# MSP430FR5739 register map
File version: 1.1
CPU: msp430
Registers are 16-bit, access not given, reset 0x0 unless marked. A register's access mark holds for its fields unless they carry their own. Offsets are from the block's base; [hi:lo] are bit positions; {n}, {i} and the like mark numbered series.

## USCI_B0__I2C_Mode
Base 0x00000000
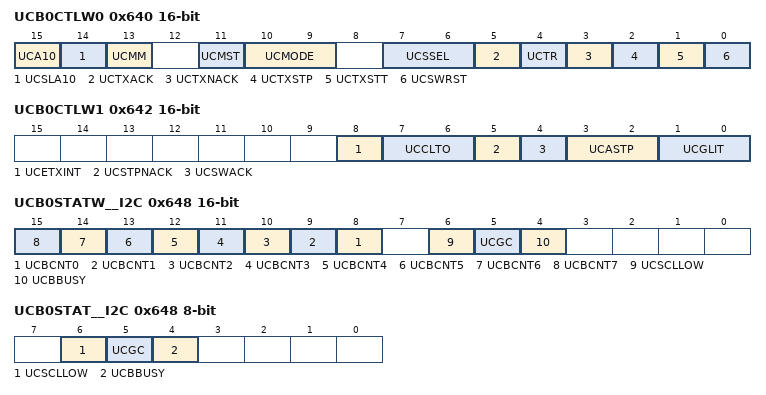
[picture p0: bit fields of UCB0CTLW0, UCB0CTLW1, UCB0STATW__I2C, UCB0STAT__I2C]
0x640 UCB0CTLW0 — USCI B0 Control Word Register 0
  [15] UCA10 — [15:15] 10-bit Address Mode
  [14] UCSLA10 — [14:14] 10-bit Slave Address Mode
  [13] UCMM — [13:13] Multi-Master Environment
  [11] UCMST — [11:11] Sync. Mode: Master Select
  [10:9] UCMODE — [10:9] Sync. Mode: USCI Mode 1
    {v}=Sync. Mode: USCI Mode: {v} (v=0..3)
  [7:6] UCSSEL — [7:6] USCI 1 Clock Source Select 1
    {v}=USCI 0 Clock Source: {v} (v=0..3)
  [5] UCTXACK — [5:5] Transmit ACK
  [4] UCTR — [4:4] Transmit/Receive Select/Flag
  [3] UCTXNACK — [3:3] Transmit NACK
  [2] UCTXSTP — [2:2] Transmit STOP
  [1] UCTXSTT — [1:1] Transmit START
  [0] UCSWRST — [0:0] USCI Software Reset
0x640 UCB0CTL1 8-bit — USCI B0 Control Register 1
0x641 UCB0CTL0 8-bit — USCI B0 Control Register 0
0x642 UCB0CTLW1 — USCI B0 Control Word Register 1
  [8] UCETXINT — [8:8] USCI Early UCTXIFG0
  [7:6] UCCLTO — [7:6] USCI Clock low timeout Bit: 1
    {v}=USCI Clock low timeout: {v} (v=0..3)
  [5] UCSTPNACK — [5:5] USCI Acknowledge Stop last byte
  [4] UCSWACK — [4:4] USCI Software controlled ACK
  [3:2] UCASTP — [3:2] USCI Automatic Stop condition generation Bit: 1
    {v}=USCI Automatic Stop condition generation: {v} (v=0..3)
  [1:0] UCGLIT — [1:0] USCI Deglitch time Bit: 1
    {v}=USCI Deglitch time: {v} (v=0..3)
0x646 UCB0BRW — USCI B0 Baud Word Rate 0
0x646 UCB0BR0 8-bit — USCI B0 Baud Rate 0
0x647 UCB0BR1 8-bit — USCI B0 Baud Rate 1
0x648 UCB0STATW — USCI B0 Status Word Register
0x648 UCB0STATW__I2C — USCI B0 Status Register
  [n+8] UCBCNT{n} (n=0..7) — [{n+8}:{n+8}] USCI Byte Counter Bit {n}
  [6] UCSCLLOW — [6:6] SCL low
  [5] UCGC — [5:5] General Call address received Flag
  [4] UCBBUSY — [4:4] Bus Busy Flag
0x648 UCB0STAT__I2C 8-bit — USCI B0 Status Register
  [6] UCSCLLOW — [6:6] SCL low
  [5] UCGC — [5:5] General Call address received Flag
  [4] UCBBUSY — [4:4] Bus Busy Flag
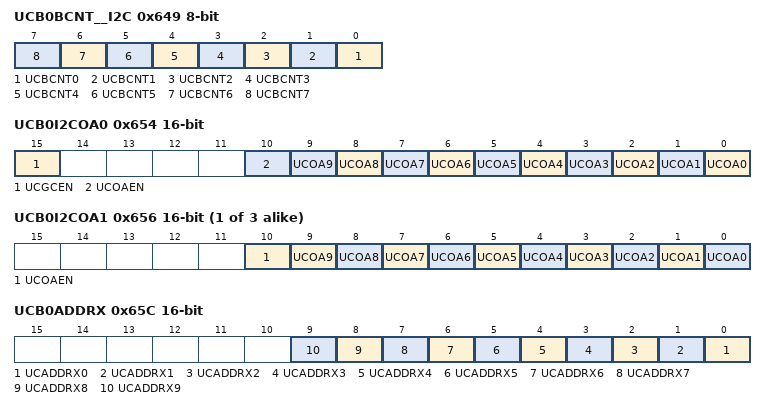
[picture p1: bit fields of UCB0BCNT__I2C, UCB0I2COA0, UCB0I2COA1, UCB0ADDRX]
0x649 UCB0BCNT__I2C 8-bit — USCI B0 Byte Counter Register
  [n] UCBCNT{n} (n=0..7) — [{n}:{n}] USCI Byte Counter Bit {n}
0x64A UCB0TBCNT — USCI B0 Byte Counter Threshold Register
0x64C UCB0RXBUF — USCI B0 Receive Buffer
0x64E UCB0TXBUF — USCI B0 Transmit Buffer
0x654 UCB0I2COA0 — USCI B0 I2C Own Address 0
  [15] UCGCEN — [15:15] I2C General Call enable
  [10] UCOAEN — [10:10] I2C Own Address enable
  [n] UCOA{n} (n=0..9) — [{n}:{n}] I2C Own Address Bit {n}
{0x654+2i} UCB0I2COA{i} (i=1..3) — USCI B0 I2C Own Address {i}
  [10] UCOAEN — [10:10] I2C Own Address enable
  [n] UCOA{n} (n=0..9) — [{n}:{n}] I2C Own Address Bit {n}
0x65C UCB0ADDRX — USCI B0 Received Address Register
  [n] UCADDRX{n} (n=0..9) — [{n}:{n}] I2C Receive Address Bit {n}
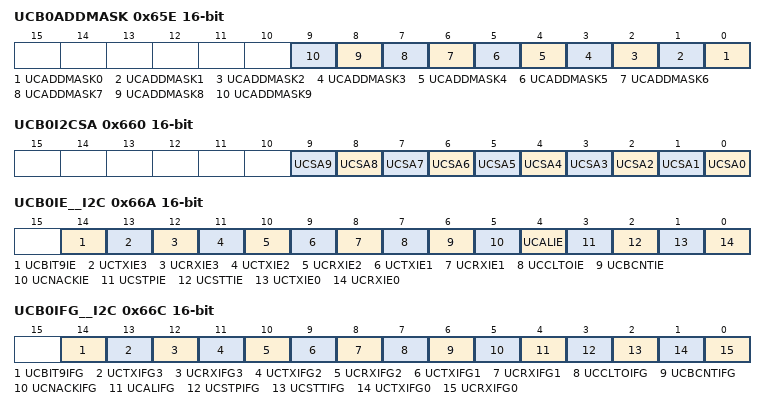
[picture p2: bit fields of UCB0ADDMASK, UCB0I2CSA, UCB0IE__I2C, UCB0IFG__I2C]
0x65E UCB0ADDMASK — USCI B0 Address Mask Register
  [n] UCADDMASK{n} (n=0..9) — [{n}:{n}] I2C Address Mask Bit {n}
0x660 UCB0I2CSA — USCI B0 I2C Slave Address
  [n] UCSA{n} (n=0..9) — [{n}:{n}] I2C Slave Address Bit {n}
0x66A UCB0IE — USCI B0 Interrupt Enable Register
0x66A UCB0IE__I2C — USCI B0 Interrupt Enable Register
  [14] UCBIT9IE — [14:14] I2C Bit 9 Position Interrupt Enable 3
  [13] UCTXIE3 — [13:13] I2C Transmit Interrupt Enable 3
  [12] UCRXIE3 — [12:12] I2C Receive Interrupt Enable 3
  [11] UCTXIE2 — [11:11] I2C Transmit Interrupt Enable 2
  [10] UCRXIE2 — [10:10] I2C Receive Interrupt Enable 2
  [9] UCTXIE1 — [9:9] I2C Transmit Interrupt Enable 1
  [8] UCRXIE1 — [8:8] I2C Receive Interrupt Enable 1
  [7] UCCLTOIE — [7:7] I2C Clock Low Timeout interrupt enable
  [6] UCBCNTIE — [6:6] I2C Automatic stop assertion interrupt enable
  [5] UCNACKIE — [5:5] I2C NACK Condition interrupt enable
  [4] UCALIE — [4:4] I2C Arbitration Lost interrupt enable
  [3] UCSTPIE — [3:3] I2C STOP Condition interrupt enable
  [2] UCSTTIE — [2:2] I2C START Condition interrupt enable
  [1] UCTXIE0 — [1:1] I2C Transmit Interrupt Enable 0
  [0] UCRXIE0 — [0:0] I2C Receive Interrupt Enable 0
0x66C UCB0IFG — USCI B0 Interrupt Flags Register
0x66C UCB0IFG__I2C — USCI B0 Interrupt Flags Register
  [14] UCBIT9IFG — [14:14] I2C Bit 9 Possition Interrupt Flag 3
  [13] UCTXIFG3 — [13:13] I2C Transmit Interrupt Flag 3
  [12] UCRXIFG3 — [12:12] I2C Receive Interrupt Flag 3
  [11] UCTXIFG2 — [11:11] I2C Transmit Interrupt Flag 2
  [10] UCRXIFG2 — [10:10] I2C Receive Interrupt Flag 2
  [9] UCTXIFG1 — [9:9] I2C Transmit Interrupt Flag 1
  [8] UCRXIFG1 — [8:8] I2C Receive Interrupt Flag 1
  [7] UCCLTOIFG — [7:7] I2C Clock low Timeout interrupt Flag
  [6] UCBCNTIFG — [6:6] I2C Byte counter interrupt flag
  [5] UCNACKIFG — [5:5] I2C NACK Condition interrupt Flag
  [4] UCALIFG — [4:4] I2C Arbitration Lost interrupt Flag
  [3] UCSTPIFG — [3:3] I2C STOP Condition interrupt Flag
  [2] UCSTTIFG — [2:2] I2C START Condition interrupt Flag
  [1] UCTXIFG0 — [1:1] I2C Transmit Interrupt Flag 0
  [0] UCRXIFG0 — [0:0] I2C Receive Interrupt Flag 0
0x66E UCB0IV — USCI B0 Interrupt Vector Register
